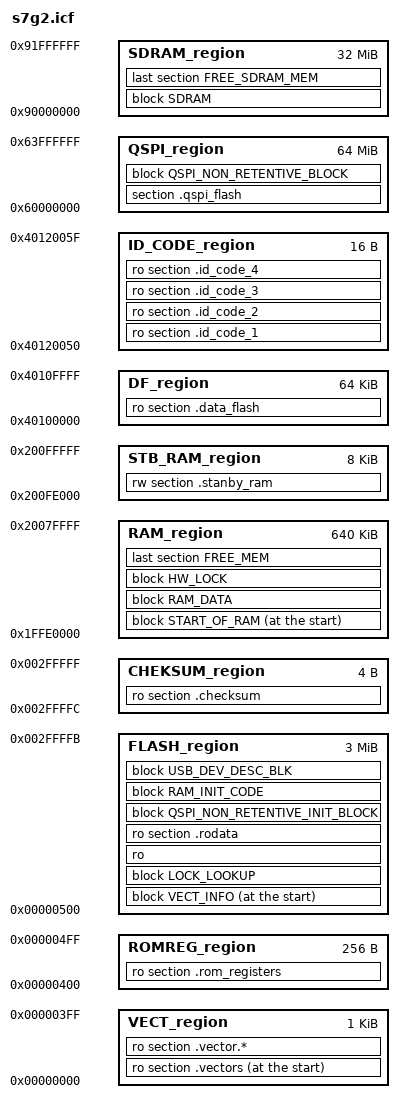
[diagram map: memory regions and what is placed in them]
define symbol region_VECT_start         = 0x00000000;
define symbol region_VECT_end           = 0x000003FF;
define symbol region_ROMREG_start       = 0x00000400;
define symbol region_ROMREG_end         = 0x000004FF;

define symbol region_FLASH_start        = 0x00000500; 
define symbol region_FLASH_end          = 0x002FFFFB;

/* Место хранения контрольной суммы для проверки целостности программы*/ 
define symbol region_CRC_start          = 0x002FFFFC; 
define symbol region_CRC_end            = 0x002FFFFF;


define symbol region_RAM_start          = 0x1FFE0000;
define symbol region_RAM_end            = 0x2007FFFF;
define symbol region_STB_RAM_start      = 0x200FE000;
define symbol region_STB_RAM_end        = 0x200FFFFF;
define symbol region_DF_start           = 0x40100000;
define symbol region_DF_end             = 0x4010FFFF;
define symbol region_SDRAM_start        = 0x90000000;
define symbol region_SDRAM_end          = 0x91FFFFFF;
define symbol region_QSPI_start         = 0x60000000;
define symbol region_QSPI_end           = 0x63FFFFFF;

define symbol region_ID_CODES_start    = 0x40120050;
define symbol region_ID_CODES_end      = 0x4012005F;

/* Stack and heap sizes are defined in bsp_cfg.h */

define memory mem with size     = 4G;
define region VECT_region       = mem:[from region_VECT_start    to region_VECT_end];
define region ROMREG_region     = mem:[from region_ROMREG_start  to region_ROMREG_end];
define region FLASH_region      = mem:[from region_FLASH_start   to region_FLASH_end];
define region RAM_region        = mem:[from region_RAM_start     to region_RAM_end];
define region STB_RAM_region    = mem:[from region_STB_RAM_start to region_STB_RAM_end];
define region DF_region         = mem:[from region_DF_start      to region_DF_end];
define region SDRAM_region      = mem:[from region_SDRAM_start   to region_SDRAM_end];
define region QSPI_region       = mem:[from region_QSPI_start    to region_QSPI_end];
define region CHEKSUM_region    = mem:[from region_CRC_start     to region_CRC_end];

define region ID_CODE_region    = mem:[from region_ID_CODES_start   to region_ID_CODES_end];

initialize manually                        { readwrite                           };
initialize manually                        { section     .qspi_non_retentive     };
do not initialize                          { section     .qspi_flash             };
do not initialize                          { section     .sdram                  };
do not initialize                          { zeroinit                            };
initialize manually                        { section     .code_in_ram            };

/* Main thread local storage */                                                
initialize manually                        { section     __DLIB_PERTHREAD        };
                                                                                 
define block RAM_INIT_CODE                 { section    .code_in_ram_init        };
define block RAM_CODE                      { section    .code_in_ram             };

define block QSPI_NON_RETENTIVE_INIT_BLOCK { section    .qspi_non_retentive_init };
define block QSPI_NON_RETENTIVE_BLOCK      { section    .qspi_non_retentive      };
define block VECT_INFO                     { ro section .vector_info.*           };
keep                                       { section    .vector*                 };
define block LOCK_LOOKUP                   { ro section .hw_lock_lookup.*        };
keep                                       { section    .hw_lock_lookup*         };
define block HW_LOCK with alignment=1      { rw section .hw_lock.*               };
keep                                       { section    .hw_lock.*               };

define block USB_DEV_DESC_BLK with fixed order, alignment = 1
                                           { ro data section .usb_device_desc_fs,
                                             ro data section .usb_config_desc_fs,
                                             ro data section .usb_interface_desc_fs,
                                             ro data section .usb_device_desc_hs,
                                             ro data section .usb_config_desc_hs,
                                             ro data section .usb_interface_desc_hs,
                                             ro data section .usb_dev_descriptor_start_fs,
                                             ro data section .usb_descriptor_end_fs };
keep                                       { section .usb_*};

define block SDRAM                         { rw section .sdram, rw section .frame };

place in CHEKSUM_region                    { ro section .checksum                 };
                                                                                  
place at start of VECT_region              { ro section .vectors                  };
place in VECT_region                       { ro section .vector.*                 };
place in ROMREG_region                     { ro section .rom_registers            };
place at start of FLASH_region             { block VECT_INFO                      };
place in FLASH_region                      { block LOCK_LOOKUP, ro, ro section .rodata, block QSPI_NON_RETENTIVE_INIT_BLOCK, block RAM_INIT_CODE, block USB_DEV_DESC_BLK };

/* If DTC is used, put the DTC vector table at the start of SRAM. This avoids memory holes due to 1K alignment required by it. */
define block START_OF_RAM                  { rw section .ssp_dtc_vector_table, block RAM_CODE, rw section .mempools };
place at start of RAM_region               { block START_OF_RAM                                                     };

define block RAM_DATA with fixed order     { rw ,rw section .bss, rw section .data, rw section .noinit, rw section HEAP, rw section .stack* };

place in RAM_region                        { block RAM_DATA,  block HW_LOCK, last section FREE_MEM };
                                           
place in DF_region                         { ro section .data_flash                                };
place in SDRAM_region                      { block SDRAM                                           };                          
place in QSPI_region                       { section .qspi_flash                                   };
place in QSPI_region                       { block QSPI_NON_RETENTIVE_BLOCK                        };
place in SDRAM_region                      { last section FREE_SDRAM_MEM                           };
place in ID_CODE_region                    { ro section .id_code_1, ro section .id_code_2, ro section .id_code_3, ro section .id_code_4 };
                                           
place in STB_RAM_region                    {rw section  .stanby_ram                                };
do not initialize                          {rw section  .stanby_ram                                };


define exported symbol __qspi_region_max_size__      = size(QSPI_region);
define exported symbol __qspi_region_start_address__ = region_QSPI_start;
define exported symbol __qspi_region_end_address__   = region_QSPI_end;

define exported symbol __VECT_start__                = region_VECT_start;
define exported symbol __vector_table                = region_VECT_start;
